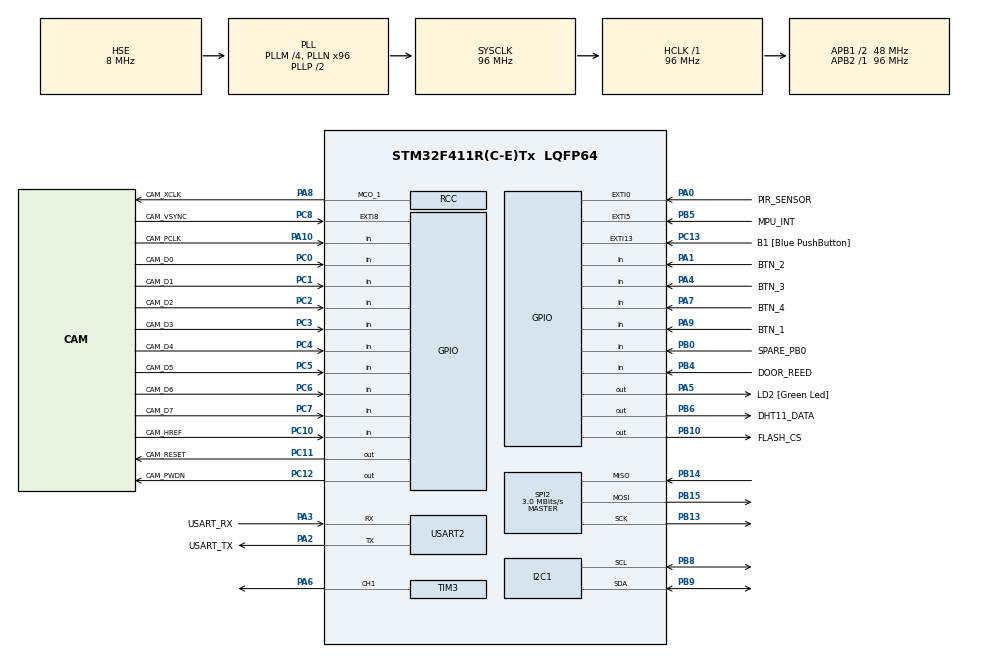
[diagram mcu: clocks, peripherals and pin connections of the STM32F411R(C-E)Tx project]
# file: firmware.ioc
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Mcu.Family=STM32F4
Mcu.Name=STM32F411R(C-E)Tx
Mcu.Package=LQFP64
NVIC.EXTI0_IRQn=true\:0\:0\:false\:false\:true\:true\:true\:true
NVIC.EXTI15_10_IRQn=true\:0\:0\:false\:false\:true\:true\:true\:true
NVIC.EXTI9_5_IRQn=true\:0\:0\:false\:false\:true\:true\:true\:true
NVIC.PriorityGroup=NVIC_PRIORITYGROUP_4
PA0-WKUP.GPIO_Label=PIR_SENSOR
PA0-WKUP.GPIO_ModeDefaultEXTI=GPIO_MODE_IT_RISING
PA0-WKUP.GPIO_PuPd=GPIO_PULLDOWN
PA0-WKUP.Signal=GPXTI0
PA1.GPIO_Label=BTN_2
PA1.GPIO_PuPd=GPIO_PULLUP
PA1.Signal=GPIO_Input
PA10.GPIO_Label=CAM_PCLK
PA10.Signal=GPIO_Input
PA13.GPIO_Label=TMS
PA13.Mode=Trace_Asynchronous_SW
PA13.Signal=SYS_JTMS-SWDIO
PA14.GPIO_Label=TCK
PA14.Mode=Trace_Asynchronous_SW
PA14.Signal=SYS_JTCK-SWCLK
PA2.GPIO_Label=USART_TX
PA2.Mode=Asynchronous
PA2.Signal=USART2_TX
PA3.GPIO_Label=USART_RX
PA3.Mode=Asynchronous
PA3.Signal=USART2_RX
PA4.GPIO_Label=BTN_3
PA4.GPIO_PuPd=GPIO_PULLUP
PA4.Signal=GPIO_Input
PA5.GPIO_Label=LD2 [Green Led]
PA5.Signal=GPIO_Output
PA6.Signal=S_TIM3_CH1
PA7.GPIO_Label=BTN_4
PA7.GPIO_PuPd=GPIO_PULLUP
PA7.Signal=GPIO_Input
PA8.GPIO_Label=CAM_XCLK
PA8.GPIO_Speed=GPIO_SPEED_FREQ_VERY_HIGH
PA8.Mode=Clock-out-1
PA8.Signal=RCC_MCO_1
PA9.GPIO_Label=BTN_1
PA9.GPIO_PuPd=GPIO_PULLUP
PA9.Signal=GPIO_Input
PB0.GPIO_Label=SPARE_PB0
PB0.GPIO_PuPd=GPIO_PULLUP
PB0.Signal=GPIO_Input
PB10.GPIO_Label=FLASH_CS
PB10.GPIO_PuPd=GPIO_PULLUP
PB10.PinState=GPIO_PIN_SET
PB10.Signal=GPIO_Output
PB13.Mode=Full_Duplex_Master
PB13.Signal=SPI2_SCK
PB14.Mode=Full_Duplex_Master
PB14.Signal=SPI2_MISO
PB15.Mode=Full_Duplex_Master
PB15.Signal=SPI2_MOSI
PB3.GPIO_Label=SWO
PB3.Mode=Trace_Asynchronous_SW
PB3.Signal=SYS_JTDO-SWO
PB5.GPIO_Label=MPU_INT
PB5.GPIO_ModeDefaultEXTI=GPIO_MODE_IT_RISING
PB5.Signal=GPXTI5
PB4.GPIO_Label=DOOR_REED
PB4.GPIO_PuPd=GPIO_PULLUP
PB4.Signal=GPIO_Input
PB6.GPIO_Label=DHT11_DATA
PB6.GPIO_ModeDefaultOutputPP=GPIO_MODE_OUTPUT_OD
PB6.PinState=GPIO_PIN_SET
PB6.Signal=GPIO_Output
PB8.Mode=I2C
PB8.Signal=I2C1_SCL
PB9.Mode=I2C
PB9.Signal=I2C1_SDA
PC0.GPIO_Label=CAM_D0
PC0.Signal=GPIO_Input
PC1.GPIO_Label=CAM_D1
PC1.Signal=GPIO_Input
PC10.GPIO_Label=CAM_HREF
PC10.Signal=GPIO_Input
PC11.GPIO_Label=CAM_RESET
PC11.PinState=GPIO_PIN_SET
PC11.Signal=GPIO_Output
PC12.GPIO_Label=CAM_PWDN
PC12.Signal=GPIO_Output
PC13-ANTI_TAMP.GPIO_Label=B1 [Blue PushButton]
PC13-ANTI_TAMP.GPIO_ModeDefaultEXTI=GPIO_MODE_IT_FALLING
PC13-ANTI_TAMP.Signal=GPXTI13
PC14-OSC32_IN.Mode=LSE-External-Oscillator
PC14-OSC32_IN.Signal=RCC_OSC32_IN
PC15-OSC32_OUT.Mode=LSE-External-Oscillator
PC15-OSC32_OUT.Signal=RCC_OSC32_OUT
PC2.GPIO_Label=CAM_D2
PC2.Signal=GPIO_Input
PC3.GPIO_Label=CAM_D3
PC3.Signal=GPIO_Input
PC4.GPIO_Label=CAM_D4
PC4.Signal=GPIO_Input
PC5.GPIO_Label=CAM_D5
PC5.Signal=GPIO_Input
PC6.GPIO_Label=CAM_D6
PC6.Signal=GPIO_Input
PC7.GPIO_Label=CAM_D7
PC7.Signal=GPIO_Input
PC8.GPIO_Label=CAM_VSYNC
PC8.GPIO_ModeDefaultEXTI=GPIO_MODE_IT_RISING
PC8.Signal=GPXTI8
PH0\ -\ OSC_IN.Mode=HSE-External-Clock-Source
PH0\ -\ OSC_IN.Signal=RCC_OSC_IN
PH1\ -\ OSC_OUT.Mode=HSE-External-Clock-Source
PH1\ -\ OSC_OUT.Signal=RCC_OSC_OUT
ProjectManager.HeapSize=0x200
ProjectManager.StackSize=0x400
ProjectManager.TargetToolchain=Makefile
RCC.48MHZClocksFreq_Value=48000000
RCC.AHBFreq_Value=96000000
RCC.APB1CLKDivider=RCC_HCLK_DIV2
RCC.APB1Freq_Value=48000000
RCC.APB1TimFreq_Value=96000000
RCC.APB2Freq_Value=96000000
RCC.APB2TimFreq_Value=96000000
RCC.CortexFreq_Value=96000000
RCC.FLatency-AdvancedSettings=FLASH_LATENCY_3
RCC.HCLKFreq_Value=96000000
RCC.HSE_VALUE=8000000
RCC.HSI_VALUE=16000000
RCC.PLLM=4
RCC.PLLN=96
RCC.PLLSourceVirtual=RCC_PLLSOURCE_HSE
RCC.RCC_MCO1Source=RCC_MCO1SOURCE_PLLCLK
RCC.RCC_MCODiv1=RCC_MCODIV_4
RCC.SYSCLKFreq_VALUE=96000000
RCC.SYSCLKSource=RCC_SYSCLKSOURCE_PLLCLK
RCC.VCOOutputFreq_Value=192000000
SH.S_TIM3_CH1.0=TIM3_CH1,PWM Generation1 CH1
SPI2.BaudRatePrescaler=SPI_BAUDRATEPRESCALER_16
SPI2.CalculateBaudRate=3.0 MBits/s
SPI2.Direction=SPI_DIRECTION_2LINES
SPI2.Mode=SPI_MODE_MASTER
SPI2.VirtualType=VM_MASTER
TIM3.AutoReloadPreload=TIM_AUTORELOAD_PRELOAD_ENABLE
TIM3.Channel-PWM\ Generation1\ CH1=TIM_CHANNEL_1
TIM3.Period=19999
TIM3.Prescaler=95
TIM3.Pulse-PWM\ Generation1\ CH1=1500
USART2.VirtualMode=VM_ASYNC
board=NUCLEO-F411RE

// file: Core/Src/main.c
/* USER CODE BEGIN Header */
/**
  ******************************************************************************
  * @file           : main.c
  * @brief          : Main program body
  ******************************************************************************
  * @attention
  *
  * Copyright (c) 2026 STMicroelectronics.
  * All rights reserved.
  *
  * This software is licensed under terms that can be found in the LICENSE file
  * in the root directory of this software component.
  * If no LICENSE file comes with this software, it is provided AS-IS.
  *
  ******************************************************************************
  */
/* USER CODE END Header */
#include "main.h"
#include "i2c.h"
#include "spi.h"
#include "tim.h"
#include "usart.h"
#include "gpio.h"

/* USER CODE BEGIN Includes */
#include "app.h"
#include "periph_check.h"
#include "platform.h"
/* USER CODE END Includes */

void SystemClock_Config(void);

int main(void)
{

  /* USER CODE BEGIN 1 */
  /* ЛР3 (I06): фарбування стека — до будь-яких викликів, щоб виміряти всю глибину */
  Platform_StackPaint();
  /* USER CODE END 1 */

  /* MCU Configuration--------------------------------------------------------*/

  /* Reset of all peripherals, Initializes the Flash interface and the Systick. */
  HAL_Init();

  /* Configure the system clock */
  SystemClock_Config();

  /* Initialize all configured peripherals */
  MX_GPIO_Init();
  MX_I2C1_Init();
  MX_SPI2_Init();
  MX_TIM3_Init();
  MX_USART2_UART_Init();
  /* USER CODE BEGIN 2 */
  App_Init();
  /* USER CODE END 2 */

  /* Infinite loop */
  while (1)
  {

    /* USER CODE BEGIN 3 */
    App_Loop();
  }
  /* USER CODE END 3 */
}

void SystemClock_Config(void)
{
  RCC_OscInitTypeDef RCC_OscInitStruct = {0};
  RCC_ClkInitTypeDef RCC_ClkInitStruct = {0};

  /** Configure the main internal regulator output voltage
  */
  __HAL_RCC_PWR_CLK_ENABLE();
  __HAL_PWR_VOLTAGESCALING_CONFIG(PWR_REGULATOR_VOLTAGE_SCALE1);

  /** Initializes the RCC Oscillators according to the specified parameters
  * in the RCC_OscInitTypeDef structure.
  */
  RCC_OscInitStruct.OscillatorType = RCC_OSCILLATORTYPE_HSE;
  RCC_OscInitStruct.HSEState = RCC_HSE_BYPASS;
  RCC_OscInitStruct.PLL.PLLState = RCC_PLL_ON;
  RCC_OscInitStruct.PLL.PLLSource = RCC_PLLSOURCE_HSE;
  RCC_OscInitStruct.PLL.PLLM = 4;
  RCC_OscInitStruct.PLL.PLLN = 96;
  RCC_OscInitStruct.PLL.PLLP = RCC_PLLP_DIV2;
  RCC_OscInitStruct.PLL.PLLQ = 4;
  if (HAL_RCC_OscConfig(&RCC_OscInitStruct) != HAL_OK)
  {
    Error_Handler();
  }

  /** Initializes the CPU, AHB and APB buses clocks
  */
  RCC_ClkInitStruct.ClockType = RCC_CLOCKTYPE_HCLK|RCC_CLOCKTYPE_SYSCLK
                              |RCC_CLOCKTYPE_PCLK1|RCC_CLOCKTYPE_PCLK2;
  RCC_ClkInitStruct.SYSCLKSource = RCC_SYSCLKSOURCE_PLLCLK;
  RCC_ClkInitStruct.AHBCLKDivider = RCC_SYSCLK_DIV1;
  RCC_ClkInitStruct.APB1CLKDivider = RCC_HCLK_DIV2;
  RCC_ClkInitStruct.APB2CLKDivider = RCC_HCLK_DIV1;

  if (HAL_RCC_ClockConfig(&RCC_ClkInitStruct, FLASH_LATENCY_3) != HAL_OK)
  {
    Error_Handler();
  }
  HAL_RCC_MCOConfig(RCC_MCO1, RCC_MCO1SOURCE_PLLCLK, RCC_MCODIV_4);
}

void Error_Handler(void)
{
  /* USER CODE BEGIN Error_Handler_Debug */
  /* User can add his own implementation to report the HAL error return state */
  __disable_irq();
  PeriphCheck_OnError();
  /* USER CODE END Error_Handler_Debug */
}
